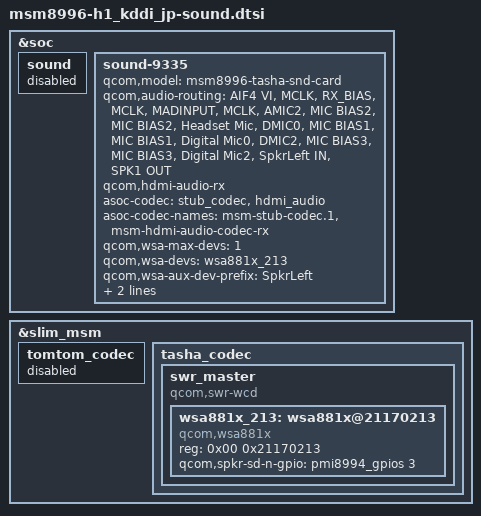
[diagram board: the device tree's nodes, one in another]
/* Copyright (c) 2015, The Linux Foundation. All rights reserved.
 *
 * This program is free software; you can redistribute it and/or modify
 * it under the terms of the GNU General Public License version 2 and
 * only version 2 as published by the Free Software Foundation.
 *
 * This program is distributed in the hope that it will be useful,
 * but WITHOUT ANY WARRANTY; without even the implied warranty of
 * MERCHANTABILITY or FITNESS FOR A PARTICULAR PURPOSE.  See the
 * GNU General Public License for more details.
 */

&soc {
	sound {
		status = "disabled";
	};

	sound-9335 {
		qcom,model = "msm8996-tasha-snd-card";

		qcom,audio-routing =
			"AIF4 VI", "MCLK",
			"RX_BIAS", "MCLK",
			"MADINPUT", "MCLK",
			"AMIC2", "MIC BIAS2",
			"MIC BIAS2", "Headset Mic",
			"DMIC0", "MIC BIAS1",
			"MIC BIAS1", "Digital Mic0",
			"DMIC2", "MIC BIAS3",
			"MIC BIAS3", "Digital Mic2",
			"SpkrLeft IN", "SPK1 OUT";

		qcom,hdmi-audio-rx;
		asoc-codec = <&stub_codec>, <&hdmi_audio>;
		asoc-codec-names = "msm-stub-codec.1", "msm-hdmi-audio-codec-rx";
		qcom,wsa-max-devs = <1>;
		qcom,wsa-devs = <&wsa881x_213>;
		qcom,wsa-aux-dev-prefix = "SpkrLeft";
		qcom,msm-mbhc-hphl-swh = <1>;
		qcom,mbhc-audio-jack-type = "4-pole-jack";
	};
};

&slim_msm {
	tomtom_codec {
		status = "disabled";
	};
	tasha_codec {
		swr_master {
			compatible = "qcom,swr-wcd";
			#address-cells = <2>;
			#size-cells = <0>;

			wsa881x_213: wsa881x@21170213 {
				compatible = "qcom,wsa881x";
				reg = <0x00 0x21170213>;
				qcom,spkr-sd-n-gpio = <&pmi8994_gpios 3 0>;
			};	
		};
	};
};
